# STM32U5F7xx register map
File version: 1.0
Registers are 32-bit, read-write, reset 0x0 unless marked. A register's access mark holds for its fields unless they carry their own. Offsets are from the block's base; [hi:lo] are bit positions; lines under a group give offsets from that group; {n}, {i} and the like mark numbered series; 'fields as' and 'values as' point back to an identical list.

## FMAC
Base 0x40021400
Same registers: FMAC_S 0x50021400
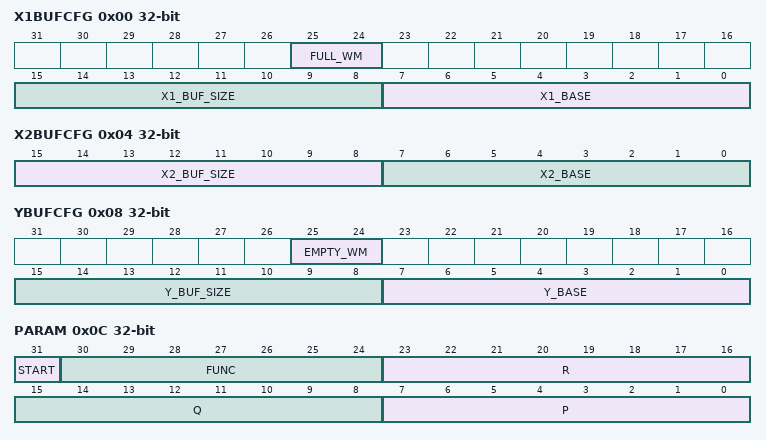
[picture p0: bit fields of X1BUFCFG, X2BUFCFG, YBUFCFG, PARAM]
0x00 X1BUFCFG — FMAC X1 Buffer Configuration register
  [25:24] FULL_WM — Watermark for buffer full flag
    0=WM_0_THRESHOLD_1; 1=WM_1_THRESHOLD_2; 2=WM_2_THRESHOLD_4; 3=WM_3_THRESHOLD_8
  [15:8] X1_BUF_SIZE — Allocated size of X1 buffer in 16-bit words
  [7:0] X1_BASE — Base address of X1 buffer
0x04 X2BUFCFG — FMAC X2 Buffer Configuration register
  [15:8] X2_BUF_SIZE — Size of X2 buffer in 16-bit words
  [7:0] X2_BASE — Base address of X2 buffer
0x08 YBUFCFG — FMAC Y Buffer Configuration register
  [25:24] EMPTY_WM — Watermark for buffer empty flag
    values as X1BUFCFG.FULL_WM
  [15:8] Y_BUF_SIZE — Size of Y buffer in 16-bit words
  [7:0] Y_BASE — Base address of Y buffer
0x0C PARAM — FMAC Parameter register
  [31] START — Enable execution
  [30:24] FUNC — Function
    1=LOAD_X1 (Load X1 buffer); 2=LOAD_X2 (Load X2 buffer); 3=LOAD_Y (Load Y buffer); 8=CONVO_FIR (Convolution (FIR filter)); 9=IIR_DIRECT_FORM_1 (IIR filter (direct form 1))
  [23:16] R — Input parameter R
  [15:8] Q — Input parameter Q
  [7:0] P — Input parameter P
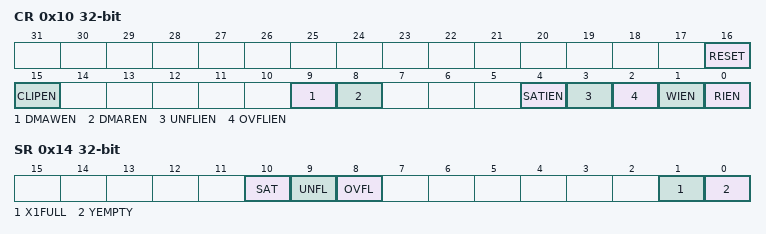
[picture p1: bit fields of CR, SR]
0x10 CR — FMAC Control register
  [16] RESET — Reset filter mathematical accelerator unit
  [15] CLIPEN — Enable clipping
  [9] DMAWEN — Enable DMA write channel requests
  [8] DMAREN — Enable DMA read channel requests
  [4] SATIEN — Enable saturation error interrupts
  [3] UNFLIEN — Enable underflow error interrupts
  [2] OVFLIEN — Enable overflow error interrupts
  [1] WIEN — Enable write interrupt
  [0] RIEN — Enable read interrupt
0x14 SR — FMAC Status register
  [10] SAT — Saturation error flag
  [9] UNFL — Underflow error flag
  [8] OVFL — Overflow error flag
  [1] X1FULL — X1 buffer full flag
  [0] YEMPTY — Y buffer empty flag
0x18 WDATA — FMAC Write Data register
  [15:0] WDATA — Write data
0x1C RDATA — FMAC Read Data register
  [15:0] RDATA — Read data

## CRC — CRC calculation unit
Base 0x40023000
Same registers: CRC_S 0x50023000
0x00 DR — CRC Data register
  [31:0] DR — Data register bits
0x04 IDR — CRC Independent data register
  [31:0] IDR — General-purpose 32-bits data register bits
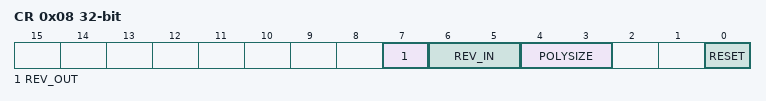
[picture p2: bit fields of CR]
0x08 CR — CRC Control register
  [7] REV_OUT — REV_OUT Reverse Output Data bits
    0=NONE (Output Data bit order not affected); 1=BIT (Output Data bit reversal done by bit)
  [6:5] REV_IN — REV_IN Reverse Input Data bits
    0=NONE (Input Data bit order not affected); 1=BYTE (Input Data bit reversal done by byte); 2=HALFWORD (Input Data bit reversal done by half-word); 3=WORD (Input Data bit reversal done by word)
  [4:3] POLYSIZE — Polynomial size bits
    0=POLYLENGTH_32B (32 bits Polynomial size); 1=POLYLENGTH_16B (16 bits Polynomial size); 2=POLYLENGTH_8B (8 bits Polynomial size); 3=POLYLENGTH_7B (7 bits Polynomial size)
  [0] RESET — RESET the CRC computation unit bit
0x10 INIT — Initial CRC value register
  [31:0] INIT — Initial CRC value bits
0x14 POL — CRC polynomial register
  [31:0] POL — Coefficients of the polynomial

## TSC — Touch Sensing Controller (TSC)
Base 0x40024000
Same registers: TSC_S 0x50024000
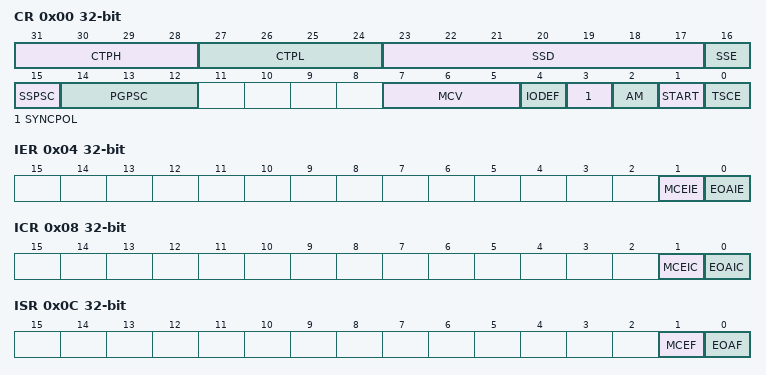
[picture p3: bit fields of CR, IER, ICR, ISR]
0x00 CR — TSC control register
  [31:28] CTPH — CTPH[3:0] bits (Charge Transfer pulse high)
  [27:24] CTPL — CTPL[3:0] bits (Charge Transfer pulse low)
  [23:17] SSD — SSD[6:0] bits (Spread Spectrum Deviation)
  [16] SSE — Spread Spectrum Enable
  [15] SSPSC — Spread Spectrum Prescaler
  [14:12] PGPSC — PGPSC[2:0] bits (Pulse Generator Prescaler)
  [7:5] MCV — MCV[2:0] bits (Max Count Value)
  [4] IODEF — IO default mode
  [3] SYNCPOL — Synchronization pin polarity
  [2] AM — Acquisition mode
  [1] START — Start acquisition
  [0] TSCE — Touch sensing controller enable
0x04 IER — TSC interrupt enable register
  [1] MCEIE — Max count error interrupt enable
  [0] EOAIE — End of acquisition interrupt enable
0x08 ICR — TSC interrupt clear register
  [1] MCEIC — Max count error interrupt clear
  [0] EOAIC — End of acquisition interrupt clear
0x0C ISR — TSC interrupt status register
  [1] MCEF — Max count error flag
  [0] EOAF — End of acquisition flag
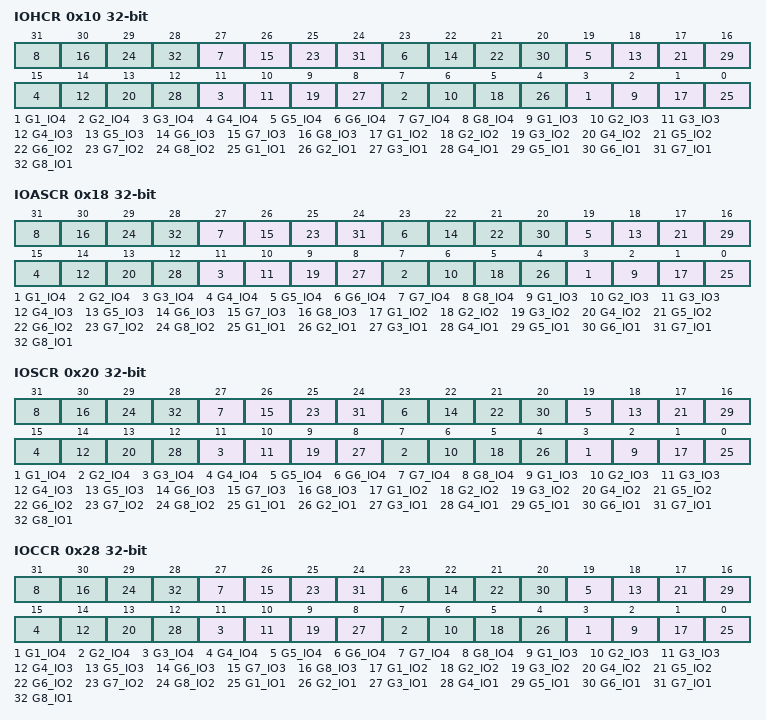
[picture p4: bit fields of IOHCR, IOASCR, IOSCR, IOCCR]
0x10 IOHCR — TSC I/O hysteresis control register
  [4n-1] G{n}_IO4 (n=1..8) — GROUP{n}_IO4 schmitt trigger hysteresis mode
  [4n-2] G{n}_IO3 (n=1..8) — GROUP{n}_IO3 schmitt trigger hysteresis mode
  [4n-3] G{n}_IO2 (n=1..8) — GROUP{n}_IO2 schmitt trigger hysteresis mode
  [4n-4] G{n}_IO1 (n=1..8) — GROUP{n}_IO1 schmitt trigger hysteresis mode
0x18 IOASCR — TSC I/O analog switch control register
  [4n-1] G{n}_IO4 (n=1..8) — GROUP{n}_IO4 analog switch enable
  [4n-2] G{n}_IO3 (n=1..8) — GROUP{n}_IO3 analog switch enable
  [4n-3] G{n}_IO2 (n=1..8) — GROUP{n}_IO2 analog switch enable
  [4n-4] G{n}_IO1 (n=1..8) — GROUP{n}_IO1 analog switch enable
0x20 IOSCR — TSC I/O sampling control register
  [4n-1] G{n}_IO4 (n=1..8) — GROUP{n}_IO4 sampling mode
  [4n-2] G{n}_IO3 (n=1..8) — GROUP{n}_IO3 sampling mode
  [4n-3] G{n}_IO2 (n=1..8) — GROUP{n}_IO2 sampling mode
  [4n-4] G{n}_IO1 (n=1..8) — GROUP{n}_IO1 sampling mode
0x28 IOCCR — TSC I/O channel control register
  [4n-1] G{n}_IO4 (n=1..8) — GROUP{n}_IO4 channel mode
  [4n-2] G{n}_IO3 (n=1..8) — GROUP{n}_IO3 channel mode
  [4n-3] G{n}_IO2 (n=1..8) — GROUP{n}_IO2 channel mode
  [4n-4] G{n}_IO1 (n=1..8) — GROUP{n}_IO1 channel mode
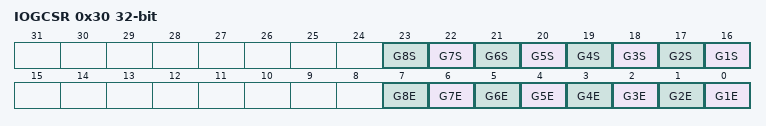
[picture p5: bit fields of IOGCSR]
0x30 IOGCSR — TSC I/O group control status register
  [n+15] G{n}S (n=1..8) — Analog IO GROUP{n} status
  [n-1] G{n}E (n=1..8) — Analog IO GROUP{n} enable
{0x30+4i} IOG{i}CR (i=1..8) — TSC I/O group x counter register
  [13:0] CNT — CNT[13:0] bits (Counter value)
